# NUC1xx_registers register map
File version: 0.1
CPU: 
Registers are 32-bit, read-write, reset 0x0 unless marked. A register's access mark holds for its fields unless they carry their own. Offsets are from the block's base; [hi:lo] are bit positions; lines under a group give offsets from that group; {n}, {i} and the like mark numbered series; 'fields as' and 'values as' point back to an identical list.

## I2C0 — Registers group
Base 0x40020000
Same registers: I2C1 0x40120000
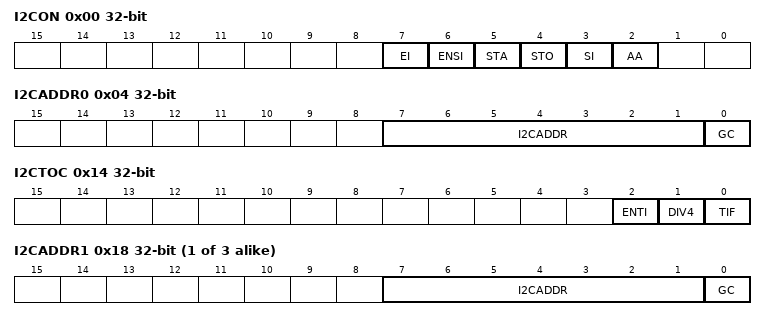
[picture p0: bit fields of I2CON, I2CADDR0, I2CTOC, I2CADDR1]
0x00 I2CON — I2C Control Register
  [7] EI — Enable Interrupt 1 = Enable I2C interrupt 0 = Disable I2C interrupt
  [6] ENSI — I2C Controller Enable Bit 1 = Enable 0 = Disable Set to enable I2C serial function block. When ENSI=1 the I2C serial function enables. The multi-function pin function of SDA and SCL must set to I2C function first.
  [5] STA — I2C START Control Bit Setting STA to logic 1 to enter master mode, the I2C hardware sends a START or repeat START condition to bus when the bus is free.
  [4] STO — I2C STOP Control Bit In master mode, setting STO to transmit a STOP condition to bus then I2C hardware will check the bus condition if a STOP condition is detected this bit will be cleared by hardware automatically. In a slave mode, setting STO resets I2C hardware to the defined "not addressed" slave mode. This means it is NO LONGER in the slave receiver mode to receive data from the master transmit device.
  [3] SI write-1-clears — I2C Interrupt Flag When a new I2C state is present in the I2CSTATUS register, the SI flag is set by hardware, and if bit EI (I2CON [7]) is set, the I2C interrupt is requested. SI must be cleared by software. Clear SI is by writing 1 to this bit.
  [2] AA — Assert Acknowledge Control Bit When AA=1 prior to address or data received, an acknowledged (low level to SDA) will be returned during the acknowledge clock pulse on the SCL line when 1.) A slave is acknowledging the address sent from master, 2.) The receiver devices are acknowledging the data sent by transmitter. When AA=0 prior to address or data received, a Not acknowledged (high level to SDA) will be returned during the acknowledge clock pulse on the SCL line.
0x04 I2CADDR0 — I2C Slave Address Register0
  [7:1] I2CADDR — I2C Address register The content of this register is irrelevant when I2C is in master mode. In the slave mode, the seven most significant bits must be loaded with the MCU's own address. The I2C hardware will react if either of the address is matched.
  [0] GC — General Call Function 0 = Disable General Call Function. 1 = Enable General Call Function.
0x08 I2CDAT — I2C Data Register
  [7:0] I2CDAT — I2C Data Register Bit[7:0] is located with the 8-bit transferred data of I2C serial port.
0x0C I2CSTATUS ro reset 0xF8 (reset mask 0xFFFFFF07)
  [7:0] I2CSTATUS — I2C Status Register The status register of I2C: The three least significant bits are always 0. The five most significant bits contain the status code. There are 26 possible status codes. When I2STATUS contains F8H, no serial interrupt is requested. All other I2CSTATUS values correspond to defined I2C states. When each of these states is entered, a status interrupt is requested (SI = 1). A valid status code is present in I2CSTATUS one machine cycle after SI is set by hardware and is still present one machine cycle after SI has been reset by software. In addition, states 00H stands for a Bus Error. A Bus Error occurs when a START or STOP condition is present at an illegal position in the formation frame. Example of illegal position are during the serial transfer of an address byte, a data byte or an acknowledge bit.
0x10 I2CLK — I2C Clock Divided Register
  [7:0] I2CLK — I2C Clock Divided Register The I2C clock rate bits: Data Baud Rate of I2C = system clock /(4x(I2CLK+1)).
0x14 I2CTOC — I2C Time-Out Control Register
  [2] ENTI — Time-out counter is enabled/disable 1 = Enable 0 = Disable When Enable, the 14 bit time-out counter will start counting when SI is clear. Setting flag SI to high will reset counter and re-start up counting after SI is cleared.
  [1] DIV4 — Time-Out counter input clock is divided by 4 1 = Enable 0 = Disable When Enable, The time-Out period is extend 4 times.
  [0] TIF write-1-clears — Time-Out Flag 1 = Time-Out falg is set by H/W. It can interrupt CPU. 0 = S/W can clear the flag.
{0x14+4i} I2CADDR{i} (i=1..3) — I2C Slave address Register{i}
  fields as I2CADDR0
{0x24+4i} I2CADM{i} (i=0..3) — I2C Slave Address Mask Register{i}
  [7:1] I2CADM — I2C Address Mask register 1 = Mask enable (the received corresponding address bit is don't care.) 0 = Mask disable (the received corresponding register bit should be exact the same as address register.) I2C bus controllers support multiple address recognition with four address mask reg. When the bit in the address mask register is set to one, it means the received corresponding address bit is don't-care. If the bit is set to zero, that means the received corresponding register bit should be exact the same as address register.
